VERSION ""

NS_ :

BS_:

BU_: Radar
VAL_TABLE_ Binary 1 "Valid" 0 "Invalid" ;

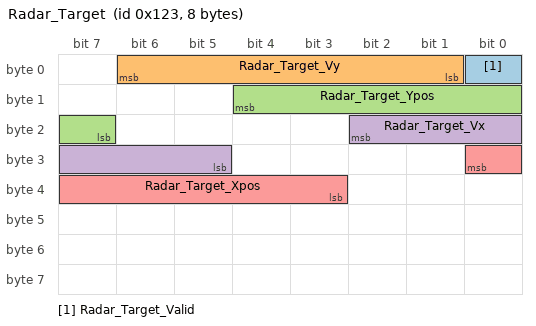
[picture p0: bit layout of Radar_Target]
BO_ 291 Radar_Target: 8 Radar
 SG_ Radar_Target_Valid : 0|1@0- (1,0) [0|0] "" Vector__XXX
 SG_ Radar_Target_Vy : 6|6@0+ (0.1,0) [0|5] "m" Vector__XXX
 SG_ Radar_Target_Ypos : 12|6@0+ (0.1,0) [0|5] "m" Vector__XXX
 SG_ Radar_Target_Vx : 18|6@0+ (0.1,0) [0|5] "m" Vector__XXX
 SG_ Radar_Target_Xpos : 24|6@0+ (0.1,0) [0|5] "m" Vector__XXX

BA_DEF_  "BusType" STRING ;
BA_DEF_DEF_  "BusType" "CAN";
VAL_ 291 Radar_Target_Valid 1 "Valid" 0 "Invalid" ;
